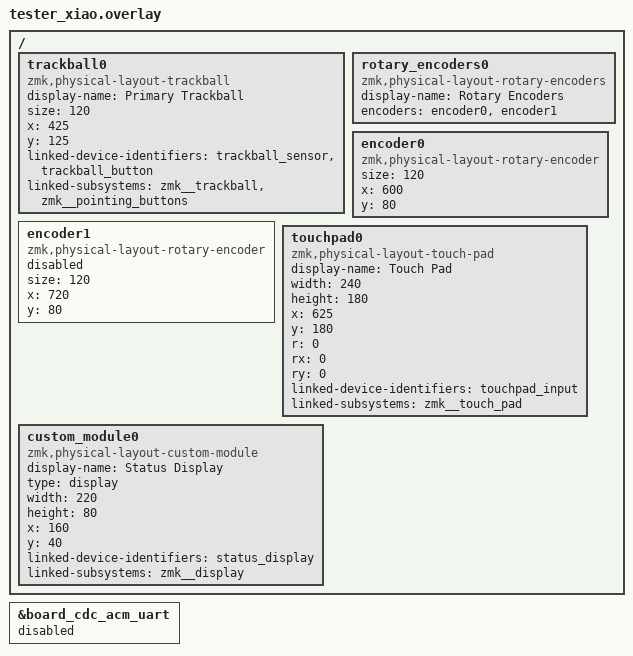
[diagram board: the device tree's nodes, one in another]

&board_cdc_acm_uart {
	status = "disabled";
};

/ {
	trackball0: trackball0 {
		compatible = "zmk,physical-layout-trackball";
		display-name = "Primary Trackball";
		size = <120>;
		x = <425>;
		y = <125>;
		linked-device-identifiers = "trackball_sensor", "trackball_button";
		linked-subsystems = "zmk__trackball", "zmk__pointing_buttons";
	};

	rotary_encoders0: rotary_encoders0 {
		compatible = "zmk,physical-layout-rotary-encoders";
		display-name = "Rotary Encoders";
		encoders = <&encoder0 &encoder1>;
	};

	encoder0: encoder0 {
		compatible = "zmk,physical-layout-rotary-encoder";
		size = <120>;
		x = <600>;
		y = <80>;
	};

	encoder1: encoder1 {
		compatible = "zmk,physical-layout-rotary-encoder";
		status = "disabled";
		size = <120>;
		x = <720>;
		y = <80>;
	};

	touchpad0: touchpad0 {
		compatible = "zmk,physical-layout-touch-pad";
		display-name = "Touch Pad";
		width = <240>;
		height = <180>;
		x = <625>;
		y = <180>;
		r = <0>;
		rx = <0>;
		ry = <0>;
		linked-device-identifiers = "touchpad_input";
		linked-subsystems = "zmk__touch_pad";
	};

	custom_module0: custom_module0 {
		compatible = "zmk,physical-layout-custom-module";
		display-name = "Status Display";
		type = "display";
		width = <220>;
		height = <80>;
		x = <160>;
		y = <40>;
		linked-device-identifiers = "status_display";
		linked-subsystems = "zmk__display";
	};
};
